# RTS591x register map
Vendor: Realtek Semiconductor Corp.; Series: RTS591x Series; File version: 1.0
CPU: ARMV8MML r0p0, little endian, MPU, FPU, VTOR, 3 interrupt priority bits, 4 SAU regions
Registers are 32-bit, read-write, reset 0x0 unless marked. A register's access mark holds for its fields unless they carry their own. Offsets are from the block's base; [hi:lo] are bit positions; {n}, {i} and the like mark numbered series; 'fields as' and 'values as' point back to an identical list.

## EMI0 — EMI Controller
Base 0x40082000
Same registers: EMI1 0x40082020, EMI2 0x40082040, EMI3 0x40082060, EMI4 0x40082080, EMI5 0x400820A0, EMI6 0x400820C0, EMI7 0x400820E0
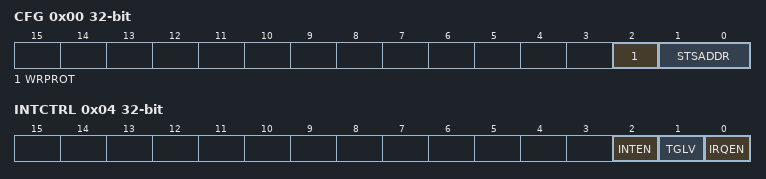
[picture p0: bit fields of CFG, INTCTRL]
0x00 CFG — CONFIGURATION REGISTER
  [2] WRPROT — Write Protect
    0=WR_ENABLE (Host write enable); 1=RD_ONLY (Host read only)
  [1:0] STSADDR — Host Status Location at Memory Base Address
    {v}=OFFSET{v} (Status is at offset #{v}) (v=0..3)
0x04 INTCTRL — INTERRUPT CONTROL REGISTER
  [2] INTEN — Interrupt Enable
    0=DISABLE (Disable interrupt); 1=ENABLE (Enable interrupt)
  [1] TGLV — Trigger Level Select
    0=LOW (Low level trigger select); 1=HIGH (High level trigger select)
  [0] IRQEN — Auto IRQ Enable
    0=DISABLE (Disabled auto IRQ); 1=ENABLE (Enable auto IRQ)
0x08 IRQNUM — IRQ NUMBER REGISTER
  [7:0] NUM — Number of IRQ
0x0C SAR — LDN RX MAPPING ADDRESS
0x10 INTSTS — INTERRUPT STATUS
  [0] STS write-1-clears — Indicate Wheather The Interrupt is Occurred
    0=NOT_OCCURRED (Interrupt is not occurred); 1=OCCURRED (Interrupt is occurred)

## GPIO — GPIO Controller
Base 0x40090000
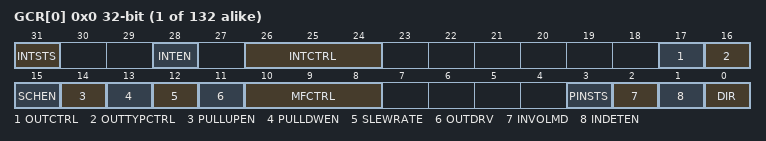
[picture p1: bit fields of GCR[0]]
{0x0+4i} GCR[{i}] (i=0..131) — CONTROL REGISTER
  [31] INTSTS write-1-clears — Interrupt Status
    0=NOT_OCCURRED (GPIO interrupt is not occurred); 1=OCCURRED (GPIO interrupt is occurred)
  [28] INTEN — Interrupt Enable
    0=DISABLE (Disable interrupt); 1=ENABLE (Enable interrupt)
  [26:24] INTCTRL — Interrupt Control
    0=POSTIVE (Trigger interrupt when positive edge occurred); 1=NEGATIVE (Trigger interrupt when negative edge occurred); 2=DUAL (Trigger interrupt when positive/negative edge occurred); 3=LOW (Trigger interrupt when low-level occurred); 4=HIGH (Trigger interrupt when high-level occurred)
  [17] OUTCTRL — Output Control
    0=LOW (Output low); 1=HIGH (Output high)
  [16] OUTTYPCTRL — Output Type Control
    0=PUSH_PULL (Push-pull mode); 1=OPEN_DRAIN (Open-drain mode)
  [15] SCHEN — Schmitter-Trigger Enable
    0=DISABLE (Disable schmitter-trigger); 1=ENABLE (Enable schmitter-trigger)
  [14] PULLUPEN — Pull-Up Enable
    0=DISABLE (Disable pull-up resistor); 1=ENABLE (Enable pull-up resistor)
  [13] PULLDWEN — Pull-Down Enable
    0=DISABLE (Disable pull-down resistor); 1=ENABLE (Enable pull-down resistor)
  [12] SLEWRATE — Slew-rate selection
    0=FAST (Fast slew-rate); 1=SLOW (Slow slew-rate)
  [11] OUTDRV — Pin Status
    0=LOW (Low driving capability); 1=HIGH (High driving capability)
  [10:8] MFCTRL — Multiple Function Control
    {v}=MFC{v} (Select multi-function[{v}]) (v=0..3)
  [3] PINSTS ro — Pin Status
    0=LOW (Pin status is low); 1=HIGH (Pin status is high)
  [2] INVOLMD — Input Voltage Mode
    0=3V3 (3V3 voltage input); 1=1V8 (1V8 voltage input)
  [1] INDETEN — Input Detection Enable
    0=DISABLE (Disable input detection); 1=ENABLE (Enable input detection)
  [0] DIR — Direction
    0=INPUT (Intput mode); 1=OUTPUT (Output mode)

## IOPAD — I/O Pad Controller
Base 0x40091000
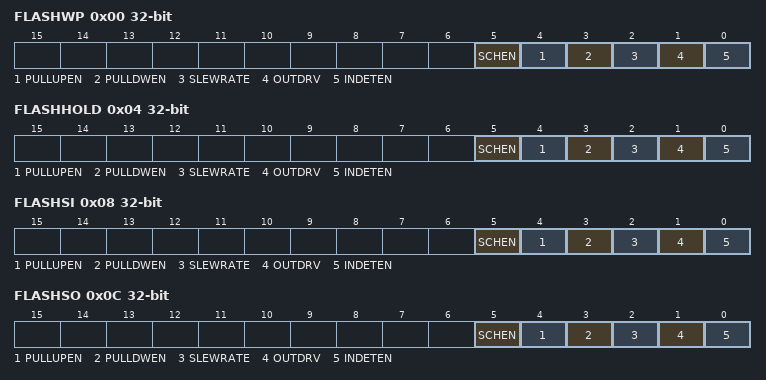
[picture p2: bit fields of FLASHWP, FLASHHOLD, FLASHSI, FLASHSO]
0x00 FLASHWP — INTERNAL FLASH_WP PAD CONTROL REGISTER
  [5] SCHEN — Schmitter-Trigger Enable
    0=DISABLE (Disable schmitter-trigger); 1=ENABLE (Enable schmitter-trigger)
  [4] PULLUPEN — Pull-Up Enable
    0=DISABLE (Disable pull-up resistor); 1=ENABLE (Enable pull-up resistor)
  [3] PULLDWEN — Pull-Down Enable
    0=DISABLE (Disable pull-down resistor); 1=ENABLE (Enable pull-down resistor)
  [2] SLEWRATE — Slew-rate selection
    0=FAST (Fast slew-rate); 1=SLOW (Slow slew-rate)
  [1] OUTDRV — Pin Status
    0=LOW (Low driving capability); 1=HIGH (High driving capability)
  [0] INDETEN — Input Detection Enable
    0=DISABLE (Disable input detection); 1=ENABLE (Enable input detection)
0x04 FLASHHOLD — INTERNAL FLASH_HOLD PAD CONTROL REGISTER
  fields as FLASHWP
0x08 FLASHSI — INTERNAL FLASH_SI PAD CONTROL REGISTER
  fields as FLASHWP
0x0C FLASHSO — INTERNAL FLASH_SO PAD CONTROL REGISTER
  fields as FLASHWP
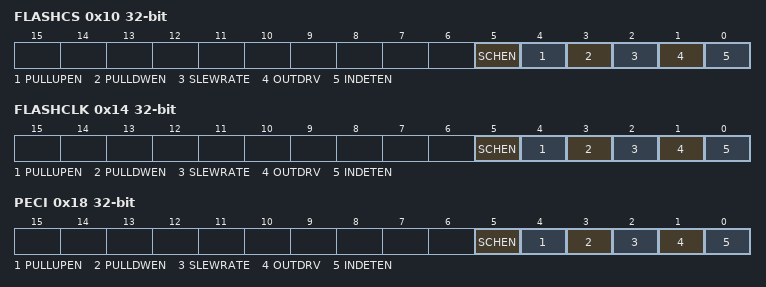
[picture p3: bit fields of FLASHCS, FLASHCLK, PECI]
0x10 FLASHCS — INTERNAL FLASH_CS PAD CONTROL REGISTER
  fields as FLASHWP
0x14 FLASHCLK — INTERNAL FLASH_CLK PAD CONTROL REGISTER
  fields as FLASHWP
0x18 PECI — PECI PAD CONTROL REGISTER
  fields as FLASHWP
